# LM3S9B96 register map
File version: 7944
Registers are 32-bit, read-write, no defined reset value unless marked. A register's access mark holds for its fields unless they carry their own. Offsets are from the block's base; [hi:lo] are bit positions; {n}, {i} and the like mark numbered series.

## COMP — Register map for COMP peripheral
Base 0x4003C000; register names take the prefix COMP
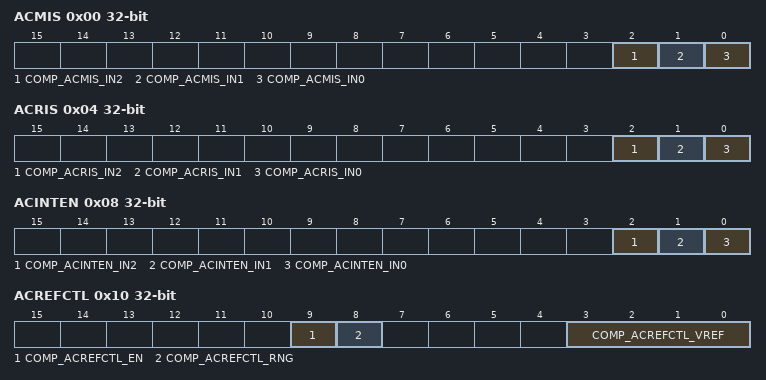
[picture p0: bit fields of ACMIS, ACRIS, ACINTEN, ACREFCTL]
0x00 ACMIS — Analog Comparator Masked Interrupt Status
  [2] COMP_ACMIS_IN2 — Comparator 2 Masked Interrupt Status
  [1] COMP_ACMIS_IN1 — Comparator 1 Masked Interrupt Status
  [0] COMP_ACMIS_IN0 — Comparator 0 Masked Interrupt Status
0x04 ACRIS — Analog Comparator Raw Interrupt Status
  [2] COMP_ACRIS_IN2 — Comparator 2 Interrupt Status
  [1] COMP_ACRIS_IN1 — Comparator 1 Interrupt Status
  [0] COMP_ACRIS_IN0 — Comparator 0 Interrupt Status
0x08 ACINTEN — Analog Comparator Interrupt Enable
  [2] COMP_ACINTEN_IN2 — Comparator 2 Interrupt Enable
  [1] COMP_ACINTEN_IN1 — Comparator 1 Interrupt Enable
  [0] COMP_ACINTEN_IN0 — Comparator 0 Interrupt Enable
0x10 ACREFCTL — Analog Comparator Reference Voltage Control
  [9] COMP_ACREFCTL_EN — Resistor Ladder Enable
  [8] COMP_ACREFCTL_RNG — Resistor Ladder Range
  [3:0] COMP_ACREFCTL_VREF — Resistor Ladder Voltage Ref
{0x20+0x20*i} ACSTAT{i} (i=0..2) — Analog Comparator Status {i}
  [1] COMP_ACSTAT{i}_OVAL — Comparator Output Value
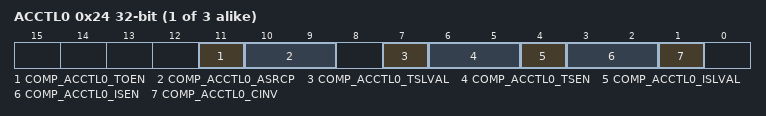
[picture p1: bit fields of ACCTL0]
{0x24+0x20*i} ACCTL{i} (i=0..2) — Analog Comparator Control {i}
  [11] COMP_ACCTL{i}_TOEN — Trigger Output Enable
  [10:9] COMP_ACCTL{i}_ASRCP — Analog Source Positive
    0=COMP_ACCTL{i}_ASRCP_PIN (Pin value of Cn+); 1=COMP_ACCTL{i}_ASRCP_PIN0 (Pin value of C0+); 2=COMP_ACCTL{i}_ASRCP_REF (Internal voltage reference (VIREF))
  [7] COMP_ACCTL{i}_TSLVAL — Trigger Sense Level Value
  [6:5] COMP_ACCTL{i}_TSEN — Trigger Sense
    0=COMP_ACCTL{i}_TSEN_LEVEL (Level sense, see TSLVAL); 1=COMP_ACCTL{i}_TSEN_FALL (Falling edge); 2=COMP_ACCTL{i}_TSEN_RISE (Rising edge); 3=COMP_ACCTL{i}_TSEN_BOTH (Either edge)
  [4] COMP_ACCTL{i}_ISLVAL — Interrupt Sense Level Value
  [3:2] COMP_ACCTL{i}_ISEN — Interrupt Sense
    0=COMP_ACCTL{i}_ISEN_LEVEL (Level sense, see ISLVAL); 1=COMP_ACCTL{i}_ISEN_FALL (Falling edge); 2=COMP_ACCTL{i}_ISEN_RISE (Rising edge); 3=COMP_ACCTL{i}_ISEN_BOTH (Either edge)
  [1] COMP_ACCTL{i}_CINV — Comparator Output Invert

## MAC — Register map for MAC peripheral
Base 0x40048000; register names take the prefix MAC
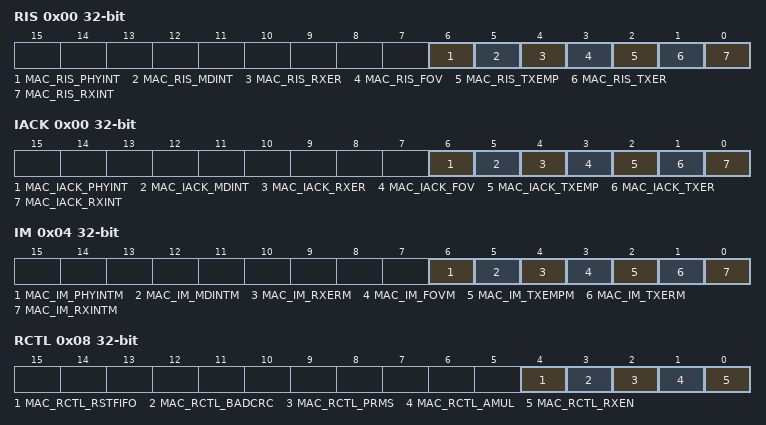
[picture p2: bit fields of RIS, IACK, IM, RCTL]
0x00 RIS — Ethernet MAC Raw Interrupt Status/Acknowledge
  [6] MAC_RIS_PHYINT — PHY Interrupt
  [5] MAC_RIS_MDINT — MII Transaction Complete
  [4] MAC_RIS_RXER — Receive Error
  [3] MAC_RIS_FOV — FIFO Overrun
  [2] MAC_RIS_TXEMP — Transmit FIFO Empty
  [1] MAC_RIS_TXER — Transmit Error
  [0] MAC_RIS_RXINT — Packet Received
0x00 IACK (MAC_ALT view) — Ethernet MAC Raw Interrupt Status/Acknowledge
  [6] MAC_IACK_PHYINT — Clear PHY Interrupt
  [5] MAC_IACK_MDINT — Clear MII Transaction Complete
  [4] MAC_IACK_RXER — Clear Receive Error
  [3] MAC_IACK_FOV — Clear FIFO Overrun
  [2] MAC_IACK_TXEMP — Clear Transmit FIFO Empty
  [1] MAC_IACK_TXER — Clear Transmit Error
  [0] MAC_IACK_RXINT — Clear Packet Received
0x04 IM — Ethernet MAC Interrupt Mask
  [6] MAC_IM_PHYINTM — Mask PHY Interrupt
  [5] MAC_IM_MDINTM — Mask MII Transaction Complete
  [4] MAC_IM_RXERM — Mask Receive Error
  [3] MAC_IM_FOVM — Mask FIFO Overrun
  [2] MAC_IM_TXEMPM — Mask Transmit FIFO Empty
  [1] MAC_IM_TXERM — Mask Transmit Error
  [0] MAC_IM_RXINTM — Mask Packet Received
0x08 RCTL — Ethernet MAC Receive Control
  [4] MAC_RCTL_RSTFIFO — Clear Receive FIFO
  [3] MAC_RCTL_BADCRC — Enable Reject Bad CRC
  [2] MAC_RCTL_PRMS — Enable Promiscuous Mode
  [1] MAC_RCTL_AMUL — Enable Multicast Frames
  [0] MAC_RCTL_RXEN — Enable Receiver
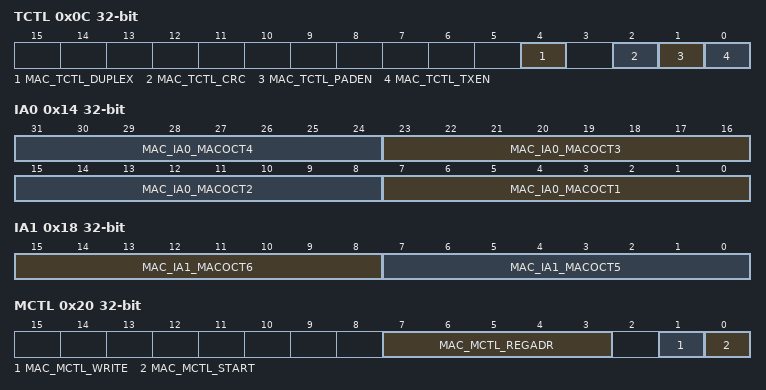
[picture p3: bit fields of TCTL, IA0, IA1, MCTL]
0x0C TCTL — Ethernet MAC Transmit Control
  [4] MAC_TCTL_DUPLEX — Enable Duplex Mode
  [2] MAC_TCTL_CRC — Enable CRC Generation
  [1] MAC_TCTL_PADEN — Enable Packet Padding
  [0] MAC_TCTL_TXEN — Enable Transmitter
0x10 DATA — Ethernet MAC Data
  [31:0] MAC_DATA_RXDATA — Receive FIFO Data
0x10 DATA (MAC_ALT view) — Ethernet MAC Data
  [31:0] MAC_DATA_TXDATA — Transmit FIFO Data
0x14 IA0 — Ethernet MAC Individual Address 0
  [8n-1:8n-8] MAC_IA0_MACOCT{n} (n=1..4) — MAC Address Octet {n}
0x18 IA1 — Ethernet MAC Individual Address 1
  [15:8] MAC_IA1_MACOCT6 — MAC Address Octet 6
  [7:0] MAC_IA1_MACOCT5 — MAC Address Octet 5
0x1C THR — Ethernet MAC Threshold
  [5:0] MAC_THR_THRESH — Threshold Value
0x20 MCTL — Ethernet MAC Management Control
  [7:3] MAC_MCTL_REGADR — MII Register Address
  [1] MAC_MCTL_WRITE — MII Register Transaction Type
  [0] MAC_MCTL_START — MII Register Transaction Enable
0x24 MDV — Ethernet MAC Management Divider
  [7:0] MAC_MDV_DIV — Clock Divider
0x2C MTXD — Ethernet MAC Management Transmit Data
  [15:0] MAC_MTXD_MDTX — MII Register Transmit Data
0x30 MRXD — Ethernet MAC Management Receive Data
  [15:0] MAC_MRXD_MDRX — MII Register Receive Data
0x34 NP — Ethernet MAC Number of Packets
  [5:0] MAC_NP_NPR — Number of Packets in Receive FIFO
0x38 TR — Ethernet MAC Transmission Request
  [0] MAC_TR_NEWTX — New Transmission
0x3C TS — Ethernet MAC Timer Support
  [0] MAC_TS_TSEN — Time Stamp Enable
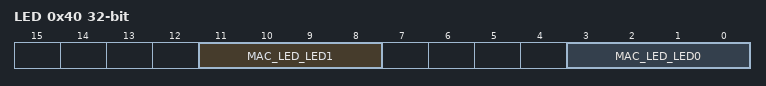
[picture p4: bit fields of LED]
0x40 LED — Ethernet MAC LED Encoding
  [11:8] MAC_LED_LED1 — LED1 Source
    0=MAC_LED_LED1_LINK (Link OK); 1=MAC_LED_LED1_RXTX (RX or TX Activity (Default LED1)); 5=100BASE-TX mode; 6=10BASE-T mode; 7=MAC_LED_LED1_DUPLEX (Full-Duplex); 8=MAC_LED_LED1_LINKACT (Link OK & Blink=RX or TX Activity)
  [3:0] MAC_LED_LED0 — LED0 Source
    0=MAC_LED_LED0_LINK (Link OK (Default LED0)); 1=MAC_LED_LED0_RXTX (RX or TX Activity); 5=100BASE-TX mode; 6=10BASE-T mode; 7=MAC_LED_LED0_DUPLEX (Full-Duplex); 8=MAC_LED_LED0_LINKACT (Link OK & Blink=RX or TX Activity)
0x44 MDIX — Ethernet PHY MDIX
  [0] MAC_MDIX_EN — MDI/MDI-X Enable
